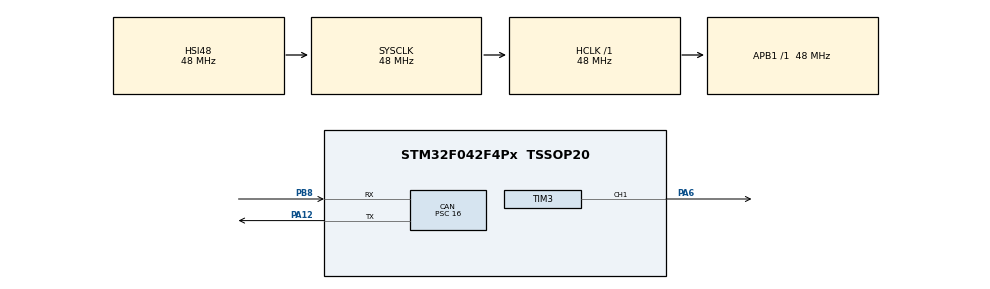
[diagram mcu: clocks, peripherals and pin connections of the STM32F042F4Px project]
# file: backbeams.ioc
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Mcu.Family=STM32F0
VP_SYS_VS_PINREMAP.Mode=PINREMAP
Dma.TIM3_CH1/TRIG.0.MemDataAlignment=DMA_MDATAALIGN_HALFWORD
Dma.TIM3_CH1/TRIG.0.PeriphInc=DMA_PINC_DISABLE
Dma.TIM3_CH1/TRIG.0.MemInc=DMA_MINC_ENABLE
RCC.SYSCLKSource=RCC_SYSCLKSOURCE_HSI48
ProjectManager.StackSize=0x400
PA13.Signal=SYS_SWDIO
PA12.Signal=CAN_TX
CAN.BS2=CAN_BS2_3TQ
CAN.Prescaler=16
CAN.BS1=CAN_BS1_8TQ
ProjectManager.TargetToolchain=STM32CubeIDE
RCC.HCLKFreq_Value=48000000
TIM3.Period=59
RCC.AHBFreq_Value=48000000
TIM3.Channel-PWM\ Generation1\ CH1=TIM_CHANNEL_1
board=custom
NVIC.DMA1_Channel4_5_IRQn=true\:0\:0\:false\:false\:true\:false\:true
Dma.TIM3_CH1/TRIG.0.PeriphDataAlignment=DMA_PDATAALIGN_HALFWORD
VP_TIM2_VS_ClockSourceINT.Mode=Internal
PA14.Mode=Serial_Wire
Dma.TIM3_CH1/TRIG.0.Priority=DMA_PRIORITY_HIGH
NVIC.TIM2_IRQn=true\:0\:0\:false\:false\:true\:true\:true
SH.S_TIM3_CH1.0=TIM3_CH1,PWM Generation1 CH1
TIM2.Period=1000
PA13.Mode=Serial_Wire
Mcu.Name=STM32F042F4Px
CAN.CalculateTimeQuantum=333.3333333333333
Dma.TIM3_CH1/TRIG.0.Mode=DMA_NORMAL
NVIC.CEC_CAN_IRQn=true\:0\:0\:false\:false\:true\:true\:true
RCC.SYSCLKFreq_VALUE=48000000
Mcu.Package=TSSOP20
TIM2.Prescaler=4800
PA6.Signal=S_TIM3_CH1
PA12.Mode=Master
Dma.TIM3_CH1/TRIG.0.Direction=DMA_MEMORY_TO_PERIPH
PA14.Signal=SYS_SWCLK
ProjectManager.HeapSize=0x200
Dma.TIM3_CH1/TRIG.0.Instance=DMA1_Channel4
PB8.Mode=Master
RCC.APB1TimFreq_Value=48000000
PB8.Signal=CAN_RX
Dma.Request0=TIM3_CH1/TRIG
RCC.APB1Freq_Value=48000000
VP_TIM3_VS_ClockSourceINT.Mode=Internal

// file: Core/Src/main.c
/* USER CODE BEGIN Header */
/**
 ******************************************************************************
 * @file           : main.c
 * @brief          : Main program body
 ******************************************************************************
 * @attention
 *
 * <h2><center>&copy; Copyright (c) 2020 Daku</center></h2>
 *
 *
 *
 ******************************************************************************
 */
/* USER CODE END Header */

#include "main.h"

/* USER CODE BEGIN PD */

/* Uncomment to set lights to front mode */
#define FRONT

#define BEAMS_CMD (0x04)
#define BEAMS_FRONT (0x00)
#define BEAMS_BACK (0x01)
#define BEAMS_ON (0x22)
#define BEAMS_OFF (0x23)
#define BEAMS_BLINK (0x62)
#define BEAMS_SOLID (0x42)

#define WS2812_ON (38)
#define WS2812_OFF (19)

#define LEDs (5)

/* USER CODE END PD */

CAN_HandleTypeDef hcan;

TIM_HandleTypeDef htim2;
TIM_HandleTypeDef htim3;
DMA_HandleTypeDef hdma_tim3_ch1_trig;

/* USER CODE BEGIN PV */

uint8_t data[255];
CAN_RxHeaderTypeDef header;

volatile uint8_t brightness = 0;
volatile uint8_t lightsOn = 0;
volatile uint8_t blink = 0;
volatile uint8_t nowBlink = 0;

uint16_t ledData[(LEDs + 4) * 24];

volatile uint8_t dmaRunning = 0;

/* USER CODE END PV */

void SystemClock_Config(void);
static void MX_GPIO_Init(void);
static void MX_DMA_Init(void);
static void MX_CAN_Init(void);
static void MX_TIM3_Init(void);
static void MX_TIM2_Init(void);
/* USER CODE BEGIN PFP */
void DMA_Complete(DMA_HandleTypeDef *hdma);

/* USER CODE END PFP */

int main(void)
{

  /* MCU Configuration--------------------------------------------------------*/

  /* Reset of all peripherals, Initializes the Flash interface and the Systick. */
  HAL_Init();

  /* Configure the system clock */
  SystemClock_Config();

  /* USER CODE BEGIN SysInit */
  HAL_Delay(500);
  /* USER CODE END SysInit */

  /* Initialize all configured peripherals */
  MX_GPIO_Init();
  MX_DMA_Init();
  MX_CAN_Init();
  MX_TIM3_Init();
  MX_TIM2_Init();
  /* USER CODE BEGIN 2 */

  CAN_TxHeaderTypeDef txHead;
  txHead.DLC = 8;
  txHead.ExtId = 0x10339200;
  txHead.IDE = CAN_ID_EXT;
  txHead.RTR = CAN_RTR_DATA;

  uint8_t txData[8];
  // initialization data
  txData[0] = 0xFE;
  txData[1] = 0x00;
  txData[2] = 0x00;
  txData[3] = 0x00;
  txData[4] = 0x00;
#ifdef FRONT
  txData[5] = 0x00;
#else
  txData[5] = 0x01;
#endif
  txData[6] = 0x37;
  txData[7] = 0x13;

  uint32_t txMb;

#ifdef FRONT
  HAL_CAN_AddTxMessage(&hcan, &txHead, &txData[0], &txMb);
#else
  HAL_CAN_AddTxMessage(&hcan, &txHead, &txData[0], &txMb);
#endif

  uint8_t tempBrightness = 0;

  /* USER CODE END 2 */

  /* Infinite loop */
  /* USER CODE BEGIN WHILE */
  while (1) {
    tempBrightness = brightness;
#ifdef FRONT
    if (blink && !nowBlink) { // currently blinking?
#else
    if (blink && !nowBlink && tempBrightness != 255) { // currently blinking and not breaking?
#endif
      tempBrightness = 0; // turn off the light, we are in a blink
    }
    while (dmaRunning) // wait for transmission to LEDs to finish
      ;

    uint16_t cnt = 48; // 2 full LEDs of LOW for resetting

    // Generate WS2812B PWM timing data.
    if (lightsOn) {
      for (int i = 0; i < LEDs; i++) {
        // 8bit green only used on front, back is red.
        for (int g = 0; g < 8; g++) {
#ifdef FRONT
          ledData[cnt++] = (tempBrightness & (0b10000000 >> g)) ? WS2812_ON : WS2812_OFF;
#else
          ledData[cnt++] = WS2812_OFF;
#endif
        }

        // 8bit red
        for (int r = 0; r < 8; r++) {
          ledData[cnt++] = (tempBrightness & (0b10000000 >> r)) ? WS2812_ON : WS2812_OFF;
        }

        // 8bit blue only used on front, back is red.
        for (int b = 0; b < 8; b++) {
#ifdef FRONT
          ledData[cnt++] = (tempBrightness & (0b10000000 >> b)) ? WS2812_ON : WS2812_OFF;
#else
          ledData[cnt++] = WS2812_OFF;
#endif
        }

      }
    } else {
      for (int i = 0; i < LEDs * 24; i++) {
        ledData[cnt++] = WS2812_OFF;
      }
    }

    dmaRunning = 1;
    // Transmit Data using PWM.
    HAL_TIM_PWM_Start_DMA(&htim3, TIM_CHANNEL_1, (uint32_t *)&ledData[0], (LEDs + 4) * 24);

    /* USER CODE END WHILE */

  }
}

void SystemClock_Config(void)
{
  RCC_OscInitTypeDef RCC_OscInitStruct = {0};
  RCC_ClkInitTypeDef RCC_ClkInitStruct = {0};

  /** Initializes the CPU, AHB and APB busses clocks
  */
  RCC_OscInitStruct.OscillatorType = RCC_OSCILLATORTYPE_HSI48;
  RCC_OscInitStruct.HSI48State = RCC_HSI48_ON;
  RCC_OscInitStruct.PLL.PLLState = RCC_PLL_NONE;
  if (HAL_RCC_OscConfig(&RCC_OscInitStruct) != HAL_OK)
  {
    Error_Handler();
  }
  /** Initializes the CPU, AHB and APB busses clocks
  */
  RCC_ClkInitStruct.ClockType = RCC_CLOCKTYPE_HCLK|RCC_CLOCKTYPE_SYSCLK
                              |RCC_CLOCKTYPE_PCLK1;
  RCC_ClkInitStruct.SYSCLKSource = RCC_SYSCLKSOURCE_HSI48;
  RCC_ClkInitStruct.AHBCLKDivider = RCC_SYSCLK_DIV1;
  RCC_ClkInitStruct.APB1CLKDivider = RCC_HCLK_DIV1;

  if (HAL_RCC_ClockConfig(&RCC_ClkInitStruct, FLASH_LATENCY_1) != HAL_OK)
  {
    Error_Handler();
  }
}

static void MX_CAN_Init(void)
{

  hcan.Instance = CAN;
  hcan.Init.Prescaler = 16;
  hcan.Init.Mode = CAN_MODE_NORMAL;
  hcan.Init.SyncJumpWidth = CAN_SJW_1TQ;
  hcan.Init.TimeSeg1 = CAN_BS1_8TQ;
  hcan.Init.TimeSeg2 = CAN_BS2_3TQ;
  hcan.Init.TimeTriggeredMode = DISABLE;
  hcan.Init.AutoBusOff = DISABLE;
  hcan.Init.AutoWakeUp = DISABLE;
  hcan.Init.AutoRetransmission = DISABLE;
  hcan.Init.ReceiveFifoLocked = DISABLE;
  hcan.Init.TransmitFifoPriority = DISABLE;
  if (HAL_CAN_Init(&hcan) != HAL_OK)
  {
    Error_Handler();
  }
  /* USER CODE BEGIN CAN_Init 2 */

  CAN_FilterTypeDef cFilter;

  cFilter.FilterActivation = CAN_FILTER_ENABLE;
  cFilter.FilterBank = 0;
  cFilter.FilterFIFOAssignment = CAN_FILTER_FIFO0;
  cFilter.FilterMode = CAN_FILTERMODE_IDMASK;
  cFilter.FilterScale = CAN_FILTERSCALE_32BIT;
  cFilter.FilterIdHigh = 0x1039;
  cFilter.FilterIdLow = 0x3200;
  cFilter.FilterMaskIdHigh = 0x0000;
  cFilter.FilterMaskIdLow = 0x0000;

  HAL_CAN_ConfigFilter(&hcan, &cFilter);

  HAL_CAN_Start(&hcan);

  HAL_CAN_ActivateNotification(&hcan, CAN_IT_RX_FIFO0_MSG_PENDING | CAN_IT_ERROR);

  /* USER CODE END CAN_Init 2 */

}

static void MX_TIM2_Init(void)
{

  TIM_ClockConfigTypeDef sClockSourceConfig = {0};
  TIM_MasterConfigTypeDef sMasterConfig = {0};

  htim2.Instance = TIM2;
  htim2.Init.Prescaler = 4800;
  htim2.Init.CounterMode = TIM_COUNTERMODE_UP;
  htim2.Init.Period = 1000;
  htim2.Init.ClockDivision = TIM_CLOCKDIVISION_DIV1;
  htim2.Init.AutoReloadPreload = TIM_AUTORELOAD_PRELOAD_DISABLE;
  if (HAL_TIM_Base_Init(&htim2) != HAL_OK)
  {
    Error_Handler();
  }
  sClockSourceConfig.ClockSource = TIM_CLOCKSOURCE_INTERNAL;
  if (HAL_TIM_ConfigClockSource(&htim2, &sClockSourceConfig) != HAL_OK)
  {
    Error_Handler();
  }
  sMasterConfig.MasterOutputTrigger = TIM_TRGO_RESET;
  sMasterConfig.MasterSlaveMode = TIM_MASTERSLAVEMODE_DISABLE;
  if (HAL_TIMEx_MasterConfigSynchronization(&htim2, &sMasterConfig) != HAL_OK)
  {
    Error_Handler();
  }
  /* USER CODE BEGIN TIM2_Init 2 */
  HAL_TIM_Base_Start_IT(&htim2);
  /* USER CODE END TIM2_Init 2 */

}

static void MX_TIM3_Init(void)
{

  TIM_ClockConfigTypeDef sClockSourceConfig = {0};
  TIM_MasterConfigTypeDef sMasterConfig = {0};
  TIM_OC_InitTypeDef sConfigOC = {0};

  htim3.Instance = TIM3;
  htim3.Init.Prescaler = 0;
  htim3.Init.CounterMode = TIM_COUNTERMODE_UP;
  htim3.Init.Period = 59;
  htim3.Init.ClockDivision = TIM_CLOCKDIVISION_DIV1;
  htim3.Init.AutoReloadPreload = TIM_AUTORELOAD_PRELOAD_DISABLE;
  if (HAL_TIM_Base_Init(&htim3) != HAL_OK)
  {
    Error_Handler();
  }
  sClockSourceConfig.ClockSource = TIM_CLOCKSOURCE_INTERNAL;
  if (HAL_TIM_ConfigClockSource(&htim3, &sClockSourceConfig) != HAL_OK)
  {
    Error_Handler();
  }
  if (HAL_TIM_PWM_Init(&htim3) != HAL_OK)
  {
    Error_Handler();
  }
  sMasterConfig.MasterOutputTrigger = TIM_TRGO_RESET;
  sMasterConfig.MasterSlaveMode = TIM_MASTERSLAVEMODE_DISABLE;
  if (HAL_TIMEx_MasterConfigSynchronization(&htim3, &sMasterConfig) != HAL_OK)
  {
    Error_Handler();
  }
  sConfigOC.OCMode = TIM_OCMODE_PWM1;
  sConfigOC.Pulse = 0;
  sConfigOC.OCPolarity = TIM_OCPOLARITY_HIGH;
  sConfigOC.OCFastMode = TIM_OCFAST_DISABLE;
  if (HAL_TIM_PWM_ConfigChannel(&htim3, &sConfigOC, TIM_CHANNEL_1) != HAL_OK)
  {
    Error_Handler();
  }
  HAL_TIM_MspPostInit(&htim3);

}

static void MX_DMA_Init(void)
{

  /* DMA controller clock enable */
  __HAL_RCC_DMA1_CLK_ENABLE();

  /* DMA interrupt init */
  /* DMA1_Channel4_5_IRQn interrupt configuration */
  HAL_NVIC_SetPriority(DMA1_Channel4_5_IRQn, 0, 0);
  HAL_NVIC_EnableIRQ(DMA1_Channel4_5_IRQn);

}

static void MX_GPIO_Init(void)
{

  /* GPIO Ports Clock Enable */
  __HAL_RCC_GPIOB_CLK_ENABLE();
  __HAL_RCC_GPIOA_CLK_ENABLE();

}

/* USER CODE BEGIN 4 */
void HAL_CAN_RxFifo0MsgPendingCallback(CAN_HandleTypeDef *hcan) {
  HAL_CAN_GetRxMessage(hcan, CAN_RX_FIFO0, &header, &data[0]);
#ifdef FRONT
  if (header.DLC == 8 && data[1] == BEAMS_CMD && data[0] == BEAMS_FRONT) {
#else
  if (header.DLC == 8 && data[1] == BEAMS_CMD && data[0] == BEAMS_BACK) {
#endif
    switch (data[2]) {
      case BEAMS_ON:
        lightsOn = 1;
#ifdef FRONT
        brightness = data[3];
#else
        brightness = data[3] * 2; // max value from board is 51 when not breaking. 102 seems like a good brightness for normal back light.
        if (brightness == 200) { // breaking, set LEDs to full brightness
          brightness = 255;
        }
#endif
        break;
      case BEAMS_OFF:
        lightsOn = 0;
        break;
      case BEAMS_BLINK:
        blink = 1;
        break;
      case BEAMS_SOLID:
        blink = 0;
        break;
      default:
        break;
    }
  }
}

void HAL_CAN_ErrorCallback(CAN_HandleTypeDef *hcan) {
  asm("NOP");
}

void HAL_TIM_PWM_PulseFinishedCallback(TIM_HandleTypeDef *htim) {

  dmaRunning = 0;
}

void HAL_TIM_PeriodElapsedCallback(TIM_HandleTypeDef *htim) {
  if (htim == &htim2)
    nowBlink ^= 1;
}

/* USER CODE END 4 */

void Error_Handler(void)
{
}
